# RA register map
Vendor: Renesas; Series: All Chips; File version: x.xx
Registers are 32-bit, read-write, reset 0x0 unless marked. A register's access mark holds for its fields unless they carry their own. Offsets are from the block's base; [hi:lo] are bit positions; lines under a group give offsets from that group; {n}, {i} and the like mark numbered series; 'fields as' and 'values as' point back to an identical list; <NAME> marks a mode.

## R_ADC0 — A/D Converter
Base 0x4005C000
Same registers: R_ADC1 0x4005C200
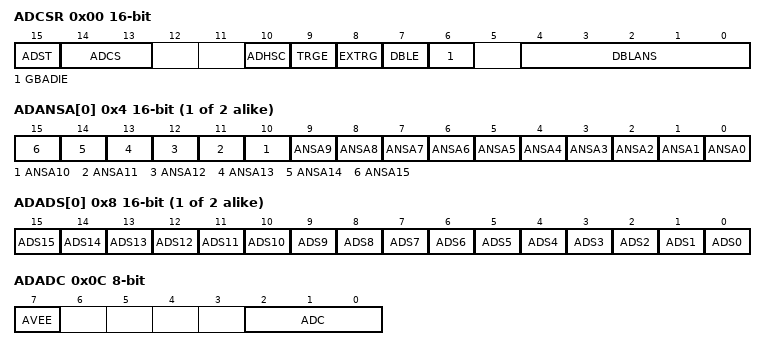
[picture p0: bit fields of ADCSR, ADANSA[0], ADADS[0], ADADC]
0x00 ADCSR 16-bit — A/D Control Register
  [15] ADST read-modifies — A/D Conversion Start
    0=Stops A/D conversion process; 1=Starts A/D conversion process
  [14:13] ADCS — Scan Mode Select
    0=Single scan mode; 1=Group scan mode; 2=Continuous scan mode; 3=Setting prohibited
  [10] ADHSC — A/D Conversion Operation Mode Select
    0=High speed A/D conversion mode; 1=Low current A/D conversion mode
  [9] TRGE — Trigger Start Enable
    0=Disables A/D conversion to be started by the synchronous or asynchronous trigger; 1=Enables A/D conversion to be started by the synchronous or asynchronous trigger
  [8] EXTRG — Trigger Select
    0=A/D conversion is started by the synchronous trigger (ELC); 1=A/D conversion is started by the asynchronous trigger (ADTRG0#)
  [7] DBLE — Double Trigger Mode Select
    0=Double trigger mode non-selection; 1=Double trigger mode selection
  [6] GBADIE — Group B Scan End Interrupt Enable
    0=Disables S12GBADI0 interrupt generation upon group B scan completion; 1=Enables S12GBADI0 interrupt generation upon group B scan completion
  [4:0] DBLANS — Double Trigger Channel SelectThese bits select one analog input channel for double triggered operation. The setting is only effective while double trigger mode is selected.
{0x4+2i} ADANSA[{i}] (i=0..1) 16-bit — A/D Channel Select Register
  [n] ANSA{n} (n=0..15) — AN Input Select
    0=AN Input is not subjected to conversion; 1=AN Input is subjected to conversion
{0x8+2i} ADADS[{i}] (i=0..1) 16-bit — A/D-Converted Value Addition/Average Channel Select Register
  [n] ADS{n} (n=0..15) — A/D-Converted Value Addition/Average Channel Select
    0=AN Input is not selected; 1=AN Input is selected
0x0C ADADC 8-bit — A/D-Converted Value Addition/Average Count Select Register
  [7] AVEE — Average Mode Enable. NOTE:When average mode is deselected by setting the ADADC.AVEE bit to 0, set the addition count to 1, 2, 3, 4 or 16-time conversion. 16-time conversion can only be used with 12-bit accuracy selected. NOTE: AVEE bit is valid at the only setting of ADC[2:0] bits = 001b or 011b. When average mode is selected by setting the ADADC.AVEE bit to 1, do not set the addition count to three times (ADADC.ADC[2:0] = 010b)
    0=Disable average mode; 1=Enable average mode
  [2:0] ADC — Addition frequency selection bit.NOTE: AVEE bit is valid at the only setting of ADC[2:0] bits = 001b or 011b. When average mode is selected by setting the ADADC.AVEE bit to 1, do not set the addition count to three times (ADADC.ADC[2:0] = 010b)
    0=1-time conversion (no addition; same as normal conversion); 1=2-time conversion (addition once); 2=3-time conversion (addition twice); 3=4-time conversion (addition three times); 5=16-time conversion (addition 15 times), can be set when selecting 12-bit accuracy; other=others (Setting prohibited)
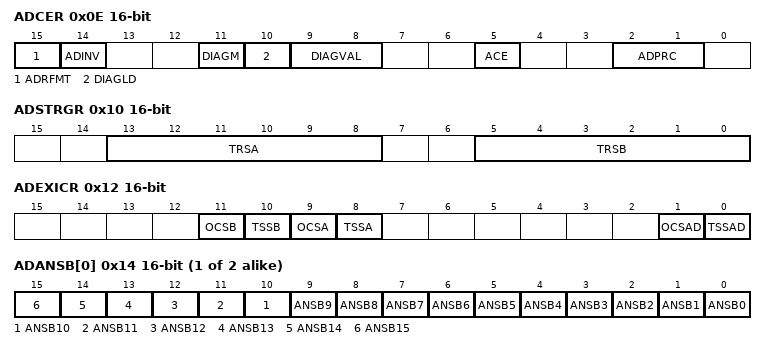
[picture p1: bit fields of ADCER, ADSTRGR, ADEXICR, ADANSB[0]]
0x0E ADCER 16-bit — A/D Control Extended Register
  [15] ADRFMT — A/D Data Register Format Select
    0=Flush-right is selected for the A/D data register format; 1=Flush-left is selected for the A/D data register format
  [14] ADINV — Single-Ended Input A/D Converted Data Inversion Select
    0=Data is stored in a range of -32768 to 0; 1=Data is stored in a range of 0 to 32767
  [11] DIAGM — Self-Diagnosis Enable
    0=Disables self-diagnosis of A/D converter; 1=Enables self-diagnosis of A/D converter
  [10] DIAGLD — Self-Diagnosis Mode Select
    0=Rotation mode for self-diagnosis voltage; 1=Fixed mode for self-diagnosis voltage
  [9:8] DIAGVAL — Self-Diagnosis Conversion Voltage Select
    0=When the self-diagnosis fixation mode is selected, it set prohibits it; 1=The self-diagnosis by using the voltage of 0V; 2=The self-diagnosis by using the voltage of reference supply x 1/2; 3=The self-diagnosis by using the voltage of the reference supply
  [5] ACE — A/D Data Register Automatic Clearing Enable
    0=Disables automatic clearing; 1=Enables automatic clearing
  [2:1] ADPRC — A/D Conversion Accuracy Specify
    0=A/D conversion is performed with 12-bit accuracy; 1=A/D conversion is performed with 10-bit accuracy; 2=A/D conversion is performed with 8-bit accuracy; 3=A/D conversion is performed with 14-bit accuracy
0x10 ADSTRGR 16-bit — A/D Conversion Start Trigger Select Register
  [13:8] TRSA — A/D Conversion Start Trigger SelectSelect the A/D conversion start trigger in single scan mode and continuous mode. In group scan mode, the A/D conversion start trigger for group A is selected.
  [5:0] TRSB — A/D Conversion Start Trigger Select for Group BSelect the A/D conversion start trigger for group B in group scan mode.
0x12 ADEXICR 16-bit — A/D Conversion Extended Input Control Register
  [11] OCSB — Internal Reference Voltage A/D Conversion Select for Group B in group scan mode.
    0=The internal reference voltage is not selected for group B in group scan mode; 1=The internal reference voltage is selected for group B in group scan mode
  [10] TSSB — Temperature Sensor Output A/D Conversion Select for Group B in group scan mode.
    0=The temperature sensor output is not selected for group B in group scan mode; 1=The temperature sensor output is selected for group B in group scan mode
  [9] OCSA — Internal Reference Voltage A/D Conversion Select
    0=The internal reference voltage is not selected; 1=The internal reference voltage is selected for group A in single scan mode, continuous scan mode, or group scan mode
  [8] TSSA — Temperature Sensor Output A/D Conversion Select
    0=The temperature sensor output is not selected; 1=The temperature sensor output is selected
  [1] OCSAD — Internal Reference Voltage A/D converted Value Addition/Average Mode Select
    0=Internal reference voltage A/D-converted value addition/average mode is not selected; 1=Internal reference voltage A/D-converted value addition/average mode is selected
  [0] TSSAD — Temperature Sensor Output A/D converted Value Addition/Average Mode Select
    0=Temperature sensor output A/D-converted value addition/average mode is not selected; 1=Temperature sensor output A/D-converted value addition/average mode is selected
{0x14+2i} ADANSB[{i}] (i=0..1) 16-bit — A/D Channel Select Register B
  [n] ANSB{n} (n=0..15) — AN Input Select
    0=Input is not subjected to conversion; 1=Input is subjected to conversion
0x18 ADDBLDR 16-bit ro — A/D Data Duplication Register
  [15:0] ADDBLDR — This is a 16-bit read-only register for storing the result of A/D conversion in response to the second trigger in double trigger mode.
0x1A ADTSDR 16-bit ro — A/D Temperature Sensor Data Register
  [15:0] ADTSDR — This is a 16-bit read-only register for storing the A/D conversion result of temperature sensor output.
0x1C ADOCDR 16-bit ro — A/D Internal Reference Voltage Data Register
  [15:0] ADOCDR — This is a 16-bit read-only register for storing the A/D result of internal reference voltage.
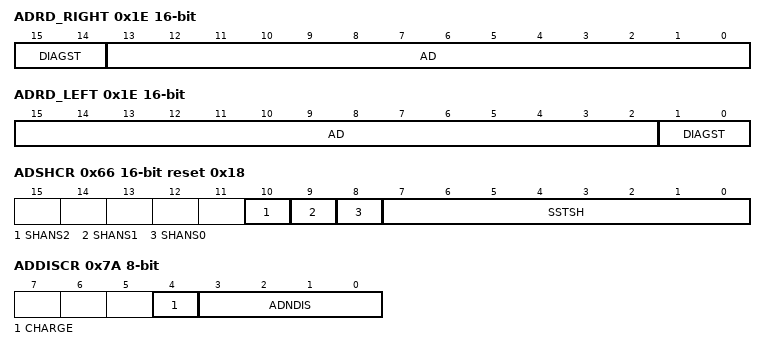
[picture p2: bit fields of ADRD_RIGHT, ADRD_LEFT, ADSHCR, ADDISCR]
0x1E ADRD_RIGHT 16-bit ro — A/D Self-Diagnosis Data Register Right Justified
  [15:14] DIAGST — Self-Diagnosis Status
    0=Self-diagnosis has never been executed since power-on; 1=Self-diagnosis using the voltage of 0 V has been executed; 2=Self-diagnosis using the voltage of reference power supply(VREFH) x 1/2 has been executed; 3=Self-diagnosis using the voltage of reference power supply(VREFH) has been executed
  [13:0] AD — A/D-converted value (right-justified)The format for data determine ADCER.ADRFMT and ADCER.ADPRC.
0x1E ADRD_LEFT 16-bit ro (alternate view of ADRD_RIGHT) — A/D Self-Diagnosis Data Register Left Justified
  [15:2] AD — A/D-converted value (right-justified)The format for data determine ADCER.ADRFMT and ADCER.ADPRC.
  [1:0] DIAGST — Self-Diagnosis Status
    values as ADRD_RIGHT.DIAGST
{0x20+2i} ADDR[{i}] (i=0..27) 16-bit ro — A/D Data Register
  [15:0] ADDR — The ADDR register is a 16-bit read-only registers for storing the result of A/D conversion.
0x66 ADSHCR 16-bit reset 0x18 — A/D Sample and Hold Circuit Control Register
  [10] SHANS2 — AN002 sample-and-hold circuit Select
    0=Bypass the sample-and-hold circuit; 1=Use the sample-and-hold circuit
  [9] SHANS1 — AN001 sample-and-hold circuit Select
    values as SHANS2
  [8] SHANS0 — AN000 sample-and-hold circuit Select
    values as SHANS2
  [7:0] SSTSH range 0x04..0xFF — Channel-Dedicated Sample-and-Hold Circuit Sampling Time Setting Set the sampling time (4 to 255 states)
0x7A ADDISCR 8-bit — A/D Disconnection Detection Control Register
  [4] CHARGE — Selection of Precharge or Discharge
    0=Discharge; 1=Precharge
  [3:0] ADNDIS — The charging time
    0=Disconnection detection is disabled; 1=Setting prohibited; other=others (( 1 / ADCLK ) x ADNDIS)
0x7C ADSHMSR 8-bit — A/D Sample and Hold Operation Mode Select Register
  [0] SHMD — Channel-Dedicated Sample-and-Hold Circuit Operation Mode Select
    0=Sampling by channel-dedicated sample-and-hold circuit is disable; 1=Sampling by channel-dedicated sample-and-hold circuit is enable
0x7D ADICR 8-bit — A/D Interrupt Control Register
  [1:0] ADIC — A/D Interrupt Control
    0=ADC_ADI is generated at end of A/D Scan; 3=ADC_ADI is generated at end of calibration
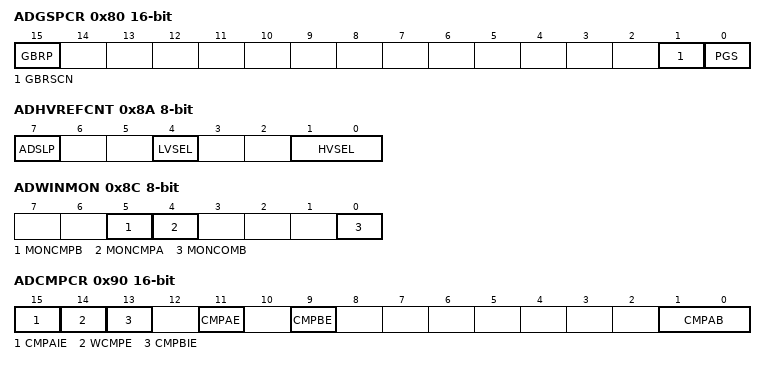
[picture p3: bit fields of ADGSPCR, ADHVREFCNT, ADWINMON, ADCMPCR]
0x80 ADGSPCR 16-bit — A/D Group Scan Priority Control Register
  [15] GBRP — Group B Single Scan Continuous Start(Enabled only when PGS = 1. Reserved when PGS = 0.)Note: When the GBRP bit has been set to 1, single scan is performed continuously for group B regardless of the setting of the GBRSCN bit.
    0=Single scan for group B is not continuously activated; 1=Single scan for group B is continuously activated
  [1] GBRSCN — Group B Restart Setting(Enabled only when PGS = 1. Reserved when PGS = 0.)
    0=Scanning for group B is not restarted after having been discontinued due to group A priority control; 1=Scanning for group B is restarted after having been discontinued due to group A priority control
  [0] PGS — Group A priority control setting bit.Note: When the PGS bit is to be set to 1, the ADCSR.ADCS[1:0] bits must be set to 01b (group scan mode). If the bits are set to any other values, proper operation is not guaranteed.
    0=Operation is without group A priority control; 1=Operation is with group A priority control
0x84 ADDBLDRA 16-bit ro — A/D Data Duplexing Register A
  [15:0] ADDBLDRA — This register is a 16-bit read-only registers for storing the result of A/D conversion in response to the respective triggers during extended operation in double trigger mode.
0x86 ADDBLDRB 16-bit ro — A/D Data Duplexing Register B
  [15:0] ADDBLDRB — This register is a 16-bit read-only registers for storing the result of A/D conversion in response to the respective triggers during extended operation in double trigger mode.
0x8A ADHVREFCNT 8-bit — A/D High-Potential/Low-Potential Reference Voltage Control Register
  [7] ADSLP — Sleep
    0=Normal operation; 1=Standby state
  [4] LVSEL — Low-Potential Reference Voltage Select
    0=AVSS0 is selected as the low-potential reference voltage; 1=VREFL0 is selected as the low-potential reference voltage
  [1:0] HVSEL — High-Potential Reference Voltage Select
    0=AVCC0 is selected as the high-potential reference voltage; 1=VREFH0 is selected as the high-potential reference voltage; 2=Internal reference voltage is selected as the high-potential reference voltage; 3=Internal node discharge. No reference voltage pin is selected.
0x8C ADWINMON 8-bit ro — A/D Compare Function Window A/B Status Monitor Register
  [5] MONCMPB — Comparison Result Monitor B
    0=Window B comparison conditions are not met; 1=Window B comparison conditions are met
  [4] MONCMPA — Comparison Result Monitor A
    0=Window A comparison conditions are not met; 1=Window A comparison conditions are met
  [0] MONCOMB — Combination result monitorThis bit indicates the combination result.This bit is valid when both window A operation and window B operation are enabled.
    0=Window A / window B composite conditions are not met; 1=Window A / window B composite conditions are met
0x90 ADCMPCR 16-bit — A/D Compare Function Control Register
  [15] CMPAIE — Compare A Interrupt Enable
    0=ADC_CMPAI interrupt is disabled when comparison conditions (window A) are met; 1=ADC_CMPAI interrupt is enabled when comparison conditions (window A) are met
  [14] WCMPE — Window Function Setting
    0=Window function is disabled. Window A and window B operate as a comparator to comparator the single value on the lower side with the A/D conversion result.; 1=Window function is enabled. Window A and window B operate as a comparator to comparator the two values on the upper and lower sides with the A/D conversion result.
  [13] CMPBIE — Compare B Interrupt Enable
    0=ADC_CMPAI interrupt is disabled when comparison conditions (window B) are met; 1=ADC_CMPAI interrupt is enabled when comparison conditions (window B) are met
  [11] CMPAE — Compare Window A Operation Enable
    0=Compare window A operation is disabled. ADC_WCMPM and ADC_WCMPUM outputs are disabled.; 1=Compare window A operation is enabled
  [9] CMPBE — Compare Window B Operation Enable
    0=Compare window B operation is disabled. ADC_WCMPM and ADC_WCMPUM outputs are disabled.; 1=Compare window B operation is enabled
  [1:0] CMPAB — Window A/B Composite Conditions SettingNOTE: These bits are valid when both window A and window B are enabled (CMPAE = 1 and CMPBE = 1).
    0=ADC_WCMPM is output when window A comparison conditions are met OR window B comparison conditions are met. ADC_WCMPUM is output in other cases.; 1=ADC_WCMPM is output when window A comparison conditions are met EXOR window B comparison conditions are met. ADC_WCMPUM is output in other cases.; 2=ADC140_WCMPM is output when window A comparison conditions are met and window B comparison conditions are met. ADC140_WCMPUM is output in other cases.; 3=Setting prohibited
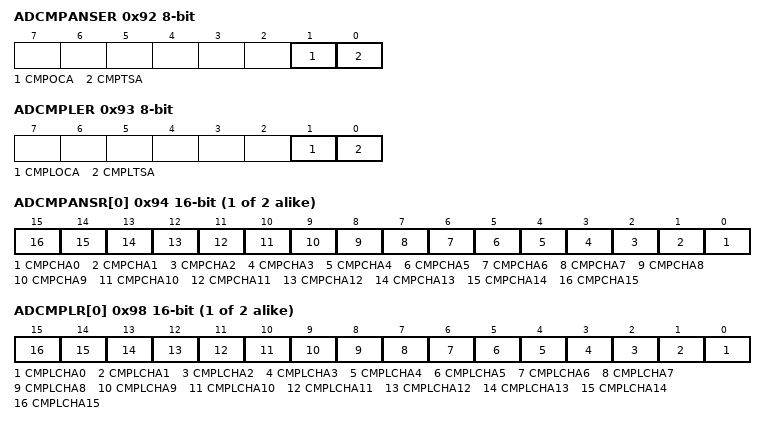
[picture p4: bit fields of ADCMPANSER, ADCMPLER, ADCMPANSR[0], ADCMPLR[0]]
0x92 ADCMPANSER 8-bit — A/D Compare Function Window A Extended Input Select Register
  [1] CMPOCA — Internal reference voltage Compare selection bit.
    0=Excludes the internal reference voltage from the compare window A target range; 1=Includes the internal reference voltage in the compare window A target range
  [0] CMPTSA — Temperature sensor output Compare selection bit.
    0=Excludes the temperature sensor output from the compare window A target range; 1=Includes the temperature sensor output in the compare window A target range
0x93 ADCMPLER 8-bit — A/D Compare Function Window A Extended Input Comparison Condition Setting Register
  [1] CMPLOCA — Compare Window A Internal Reference Voltage ComparisonCondition Select
    0=ADCMPDR0 value > A/D converted value(ADCMPCR.WCMPE=0) / A/D converted value < ADCMPDR0 value or A/D converted value > ADCMPDR1 value (ADCMPCR.WCMPE=1); 1=ADCMPDR0 value < A/D converted value(ADCMPCR.WCMPE=0) / ADCMPDR0 value < A/D converted value < ADCMPDR1 value(ADCMPCR.WCMPE=1)
  [0] CMPLTSA — Compare Window A Temperature Sensor Output Comparison Condition Select
    0=ADCMPDR0 register value > A/D-converted value(ADCMPCR.WCMPE=0) / AD-converted value < ADCMPDR0 register value or A/D-converted value > ADCMPDR1 register value(ADCMPCR.WCMPE=1); 1=ADCMPDR0 register value < A/D-converted value(ADCMPCR.WCMPE=0) / ADCMPDR0 register value < A/D-converted value < ADCMPDR1 register value(ADCMPCR.WCMPE=1)
{0x94+2i} ADCMPANSR[{i}] (i=0..1) 16-bit — A/D Compare Function Window A Channel Select Register
  [n] CMPCHA{n} (n=0..15) — AN Input Select
    0=Excludes Input from the compare window A target range; 1=Includes Input from the compare window A target range
{0x98+2i} ADCMPLR[{i}] (i=0..1) 16-bit — A/D Compare Function Window A Comparison Condition Setting Register
  [n] CMPLCHA{n} (n=0..15) — Comparison condition of input
    0=ADCMPDR0 value > A/D converted value (ADCMPCR.WCMPE=0) / A/D converted value < ADCMPDR0 value or, ADCMPDR1 value < A/D converted value (ADCMPCR.WCMPE=1); 1=ADCMPDR0 value < A/D converted value (ADCMPCR.WCMPE=0) / A/DCMPDR0 value < A/D converted value < ADCMPDR1 value (ADCMPCR.WCMPE=1)
0x9C ADCMPDR0 16-bit — A/D Compare Function Window A Lower-Side Level Setting Register
  [15:0] ADCMPDR0 — The ADCMPDR0 register sets the reference data when the compare window A function is used. ADCMPDR0 sets the lower-side level of window A.
0x9E ADCMPDR1 16-bit — A/D Compare Function Window A Upper-Side Level Setting Register
  [15:0] ADCMPDR1 — The ADCMPDR1 register sets the reference data when the compare window A function is used. ADCMPDR1 sets the upper-side level of window A..
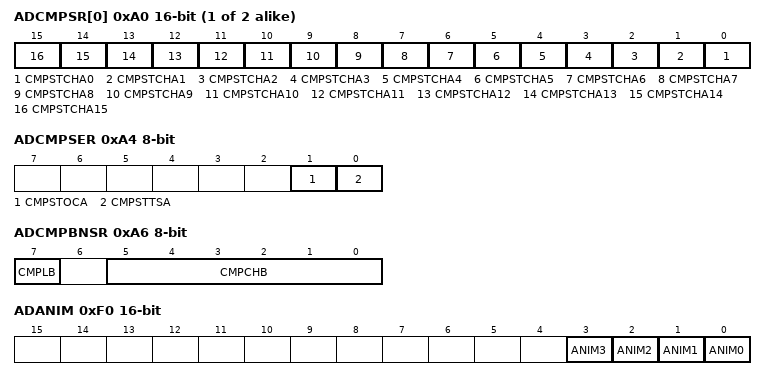
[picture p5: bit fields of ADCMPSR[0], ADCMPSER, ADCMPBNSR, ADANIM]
{0xA0+2i} ADCMPSR[{i}] (i=0..1) 16-bit — A/D Compare Function Window A Channel Status Register
  [n] CMPSTCHA{n} (n=0..15) write-0-clears read-modifies — Compare window A flag of input
    0=Comparison conditions are not met; 1=Comparison conditions are met
0xA4 ADCMPSER 8-bit — A/D Compare Function Window A Extended Input Channel Status Register
  [1] CMPSTOCA write-0-clears read-modifies — Compare Window A Internal Reference Voltage Compare Flag When window A operation is enabled (ADCMPCR.CMPAE = 1b), this bit indicates the temperature sensor output comparison result. When window A operation is disabled (ADCMPCR.CMPAE = 0b), comparison conditions for CMPSTTSA are not met any time.
    values as ADCMPSR[0].CMPSTCHA0
  [0] CMPSTTSA write-0-clears read-modifies — Compare Window A Temperature Sensor Output Compare Flag When window A operation is enabled (ADCMPCR.CMPAE = 1b), this bit indicates the temperature sensor output comparison result. When window A operation is disabled (ADCMPCR.CMPAE = 0b), comparison conditions for CMPSTTSA are not met any time.
    values as ADCMPSR[0].CMPSTCHA0
0xA6 ADCMPBNSR 8-bit — A/D Compare Function Window B Channel Selection Register
  [7] CMPLB — Compare window B Compare condition setting bit.
    0=CMPLLB value > A/D converted value (ADCMPCR.WCMPE=0) / A/D converted value < CMPLLB value or CMPULB value < A/D converted value (ADCMPCR.WCMPE=1); 1=CMPLLB value < A/D converted value(ADCMPCR.WCMPE=0) / CMPLLB value < A/D converted value < CMPULB value (ADCMPCR.WCMPE=1)
  [5:0] CMPCHB — Compare window B channel selection bit.The channel that compares it on the condition of compare window B is selected.
    {v}=AN{v:03} (v=0..27); 32=Temperature sensor; 33=Internal reference voltage; 63=No channel is selected; other=others (Setting prohibited)
0xA8 ADWINLLB 16-bit — A/D Compare Function Window B Lower-Side Level Setting Register
  [15:0] ADWINLLB — This register is used to compare A window function is used to set the lower level of the window B.
0xAA ADWINULB 16-bit — A/D Compare Function Window B Upper-Side Level Setting Register
  [15:0] ADWINULB — This register is used to compare A window function is used to set the higher level of the window B.
0xAC ADCMPBSR 8-bit — A/D Compare Function Window B Status Register
  [0] CMPSTB write-0-clears read-modifies — Compare window B flag.It is a status flag that shows the comparative result of CH (AN000-AN027, temperature sensor, and internal reference voltage) made the object of window B relation condition.
    values as ADCMPSR[0].CMPSTCHA0
0xDD ADSSTRL 8-bit reset 0xB — A/D Sampling State Register L
  [7:0] SST range 0x05..0xFF — Sampling Time Setting (AN016-AN027)
0xDE ADSSTRT 8-bit reset 0xB — A/D Sampling State Register T
  [7:0] SST range 0x05..0xFF — Sampling Time Setting (temperature sensor output)
0xDF ADSSTRO 8-bit reset 0xB — A/D Sampling State Register O
  [7:0] SST range 0x05..0xFF — Sampling Time Setting (Internal reference voltage)
{0xE0+i} ADSSTR[{i}] (i=0..15) 8-bit reset 0xB — A/D Sampling State Registers
  [7:0] SST range 0x05..0xFF — Sampling time setting
0xF0 ADANIM 16-bit — A/D Channel Input Mode Select Register
  [n] ANIM{n} (n=0..3) — Analog Channel Input Mode Select
    0=Single-end mode; 1=Differential mode
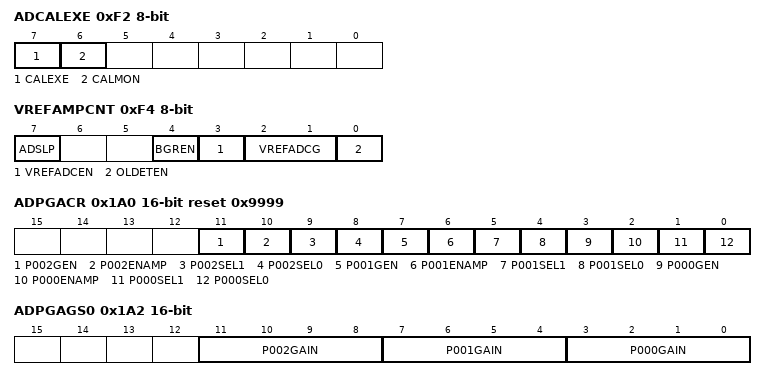
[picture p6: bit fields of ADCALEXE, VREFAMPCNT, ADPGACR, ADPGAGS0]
0xF2 ADCALEXE 8-bit — A/D Calibration Execution Register
  [7] CALEXE — Calibration Start
    0=Calibration does not start; 1=Calibration starts
  [6] CALMON ro — Calibration Status Flag
    0=Calibration not in progress; 1=Calibration in progress
0xF4 VREFAMPCNT 8-bit reset not defined — A/D Dedicated Reference Voltage Circuit Control Register
  [7] ADSLP — Sleep
    0=Normal operation; 1=Standby
  [4] BGREN — BGR Enable
    0=Turn off power of BGR; other=Turn on power of BGR
  [3] VREFADCEN — VREFADCG Enable
    0=Disable the VREFADC output; 1=Enable the VREFADC output
  [2:1] VREFADCG — VREFADC Output Voltage Control
    0=1.5 V; 2=2.0 V; 3=2.5 V
  [0] OLDETEN — OLDET Enable
    0=Disable the over current detection; other=Enable the over current detection
0xF8 ADRD 16-bit — A/D Self-Diagnosis Data Register
  [15:0] AD ro — Converted Value 15 to 0
0xFA ADRST 8-bit ro reset not defined — A/D Self-Diagnostic Status Register
  [1:0] DIAGST — Self-Diagnosis Status
    0=Self-diagnosis has not been executed since power-on; 1=Self-diagnosis was executed under a condition that the ideal value of the A/D conversion result was 8000h; 2=Self-diagnosis was executed under a condition that an ideal value of the A/D conversion result was 0000h; 3=Self-diagnosis was executed under a condition than an ideal value of the A/D conversion result is 7FFFh
0x1A0 ADPGACR 16-bit reset 0x9999 — A/D Programmable Gain Amplifier Control Register
  [11] P002GEN — PGA P002 gain setting and enable bit
    0=The gain setting is invalidated (AIN is not input in PGA); 1=The gain setting is effectively done (AIN is input in PGA)
  [10] P002ENAMP — Amplifier enable bit for PGA P002
    0=The amplifier in PGA is not used; 1=The amplifier in PGA is used
  [9] P002SEL1 — The amplifier passing is enable for PGA P002
    0=By way of the amplifier in PGA; 1=Note 1 that by way of amplifier in PGA
  [8] P002SEL0 — A through amplifier is enable for PGA P002
    0=Not through the PGA in amplifier; 1=I will through in the PGA amplifier
  [7] P001GEN — PGA P001 gain setting and enable bit
    values as P002GEN
  [6] P001ENAMP — Amplifier enable bit for PGA P001
    values as P002ENAMP
  [5] P001SEL1 — The amplifier passing is enable for PGA P001
    values as P002SEL1
  [4] P001SEL0 — A through amplifier is enable for PGA P001
    values as P002SEL0
  [3] P000GEN — PGA P000 gain setting and enable bit
    values as P002GEN
  [2] P000ENAMP — Amplifier enable bit for PGA P000
    values as P002ENAMP
  [1] P000SEL1 — The amplifier passing is enable for PGA P000
    values as P002SEL1
  [0] P000SEL0 — A through amplifier is enable for PGA P000
    values as P002SEL0
0x1A2 ADPGAGS0 16-bit — A/D Programmable Gain Amplifier Gain Setting Register 0
  [all] fields
    0=x 2.000 (ADPGADDCR0.P002DEN=0); 1=x 2.500 (ADPGADDCR0.P002DEN=0) / x 1.500 (ADPGADDCR0.P002DEN=1); 2=x 2.667 (ADPGADDCR0.P002DEN=0); 3=x 2.857 (ADPGADDCR0.P002DEN=0); 4=x 3.077 (ADPGADDCR0.P002DEN=0); 5=x 3.333 (ADPGADDCR0.P002DEN=0) / x 2.333 (ADPGADDCR0.P002DEN=1); 6=x 3.636 (ADPGADDCR0.P002DEN=0); 7=x 4.000 (ADPGADDCR0.P002DEN=0); 8=x 4.444 (ADPGADDCR0.P002DEN=0); 9=x 5.000 (ADPGADDCR0.P002DEN=0) / x 4.00 (ADPGADDCR0.P002DEN=1); 10=x 5.714 (ADPGADDCR0.P002DEN=0); 11=x 6.667 (ADPGADDCR0.P002DEN=0) / x 5.667 (ADPGADDCR0.P002DEN=1); 12=x 8.000 (ADPGADDCR0.P002DEN=0); 13=x 10.000 (ADPGADDCR0.P002DEN=0); 14=x 13.333 (ADPGADDCR0.P002DEN=0); 15=x 1.000 (for offset measurement) (ADPGADDCR0.P002DEN=0)
  [11:8] P002GAIN — PGA P002 gain setting bit.The gain magnification of (ADPGSDCR0.P002GEN=0b) when the shingle end is input and each PGA P002 is set. When the differential motion is input, (ADPGSDCR0.P002GEN=1b) sets the gain magnification when the differential motion is input by the combination with ADPGSDCR0.P002DG 1:0.
  [7:4] P001GAIN — PGA P001 gain setting bit.The gain magnification of (ADPGSDCR0.P001GEN=0b) when the shingle end is input and each PGA P001 is set. When the differential motion is input, (ADPGSDCR0.P001GEN=1b) sets the gain magnification when the differential motion is input by the combination with ADPGSDCR0.P001DG 1:0.
  [3:0] P000GAIN — PGA P000 gain setting bit.The gain magnification of (ADPGSDCR0.P000GEN=0b) when the shingle end is input and each PGA P000 is set. When the differential motion is input, (ADPGSDCR0.P000GEN=1b) sets the gain magnification when the differential motion is input by the combination with ADPGSDCR0.P000DG 1:0.
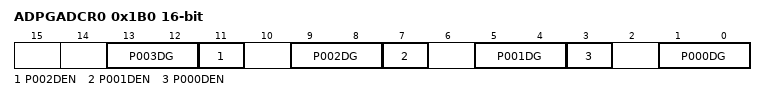
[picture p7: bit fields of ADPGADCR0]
0x1B0 ADPGADCR0 16-bit — A/D Programmable Gain Amplifier Differential Input Control Register
  [13:12] P003DG — P003 Differential Input Gain SettingNOTE: When these bits are used, set {P003DEN, P003GEN} to 11b.
    0=x 1.5; 1=x 2.333; 2=x 4.0; 3=x 5.667
  [11] P002DEN — P002 Differential Input Enable
    0=Differential input is disabled; 1=Differential input is enabled
  [9:8] P002DG — P002 Differential Input Gain SettingNOTE: When these bits are used, set {P002DEN, P002GEN} to 11b.
    0=x 1.5; 1=x 2.333; 2=x 4.0; 3=x 5.667
  [7] P001DEN — P001 Differential Input Enable
    values as P002DEN
  [5:4] P001DG — P001 Differential Input Gain SettingNOTE: When these bits are used, set {P001DEN, P001GEN} to 11b.
    0=x 1.5; 1=x 2.333; 2=x 4.0; 3=x 5.667
  [3] P000DEN — P000 Differential Input Enable
    values as P002DEN
  [1:0] P000DG — P000 Differential Input Gain SettingNOTE: When these bits are used, set {P000DEN, P000GEN} to 11b.
    0=x 1.5; 1=x 2.333; 2=x 4.0; 3=x 5.667
